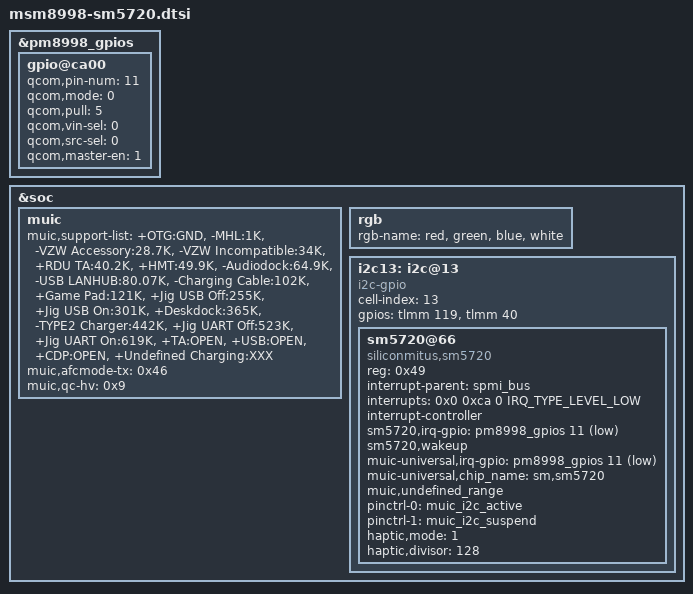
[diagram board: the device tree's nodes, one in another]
/* Copyright (c) 2012, The Linux Foundation. All rights reserved.
 *
 * This program is free software; you can redistribute it and/or modify
 * it under the terms of the GNU General Public License version 2 and
 * only version 2 as published by the Free Software Foundation.
 *
 * This program is distributed in the hope that it will be useful,
 * but WITHOUT ANY WARRANTY; without even the implied warranty of
 * MERCHANTABILITY or FITNESS FOR A PARTICULAR PURPOSE.  See the
 * GNU General Public License for more details.
 */

&pm8998_gpios {
	gpio@ca00 {
		qcom,pin-num = <11>; 
		qcom,mode = <0>; /* Digital Input*/ 
		qcom,pull = <5>; /* No pull */ 
		qcom,vin-sel = <0>;
		qcom,src-sel = <0>; /* GPIO */ 
		qcom,master-en = <1>; /* Enable GPIO */ 
		status = "okay";
	};
};

&soc {
        muic {
                status = "okay";
		muic,support-list = "+OTG:GND",
				"-MHL:1K",
				"-VZW Accessory:28.7K",
				"-VZW Incompatible:34K",
				"+RDU TA:40.2K",
				"+HMT:49.9K",
				"-Audiodock:64.9K",
				"-USB LANHUB:80.07K",
				"-Charging Cable:102K",
				"+Game Pad:121K",
				"+Jig USB Off:255K",
				"+Jig USB On:301K",
				"+Deskdock:365K",
				"-TYPE2 Charger:442K",
				"+Jig UART Off:523K",
				"+Jig UART On:619K",
				"+TA:OPEN",
				"+USB:OPEN",
				"+CDP:OPEN",
				"+Undefined Charging:XXX";
                muic,afcmode-tx = /bits/ 8 <0x46>;
		muic,qc-hv = /bits/ 8 <0x9>;
	};

	rgb {
		rgb-name = "red", "green", "blue", "white";
	};

	i2c13: i2c@13 {
		cell-index = <13>;
		compatible = "i2c-gpio";
		gpios = <&tlmm 119 0 /* sda */
			&tlmm 40 0 /* scl */
			>;
		#address-cells = <1>;
		#size-cells = <0>;

		sm5720@66 {
			compatible = "siliconmitus,sm5720";
			reg = <0x49>;
			interrupt-parent = <&spmi_bus>;
			interrupts = <0x0 0xca 0 IRQ_TYPE_LEVEL_LOW>;
			interrupt-names = "sm5720_irq";
			interrupt-controller;
			sm5720,irq-gpio = <&pm8998_gpios 11 0x01>;
			sm5720,wakeup;
			muic-universal,irq-gpio = <&pm8998_gpios 11 0x01>;
			muic-universal,chip_name = "sm,sm5720";
			muic,undefined_range;
			pinctrl-names = "muic_active", "muic_suspend";
			pinctrl-0 = <&muic_i2c_active>;
			pinctrl-1 = <&muic_i2c_suspend>;
			haptic,mode = <1>;
			haptic,divisor = <128>;
		};
	};

};

